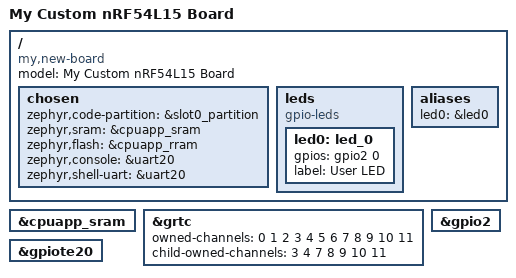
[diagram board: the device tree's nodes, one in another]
// SPDX-License-Identifier: Apache-2.0

/dts-v1/;
#include <nordic/nrf54l15_cpuapp.dtsi>

/ {
	model = "My Custom nRF54L15 Board";
	compatible = "my,new-board";

	chosen {
		zephyr,code-partition = &slot0_partition;
		zephyr,sram = &cpuapp_sram;
		zephyr,flash = &cpuapp_rram;
		zephyr,console = &uart20;
		zephyr,shell-uart = &uart20;
	};

	leds {
		compatible = "gpio-leds";
		led0: led_0 {
			gpios = <&gpio2 0 GPIO_ACTIVE_HIGH>;
			label = "User LED";
		};
	};

	aliases {
		led0 = &led0;
	};
};

&cpuapp_sram {
	status = "okay";
};

&grtc {
	owned-channels = <0 1 2 3 4 5 6 7 8 9 10 11>;
	child-owned-channels = <3 4 7 8 9 10 11>;
	status = "okay";
};


&gpio2 {
	status = "okay";
};

&gpiote20 {
	status = "okay";
};

#include <nordic/nrf54l15_partition.dtsi>
